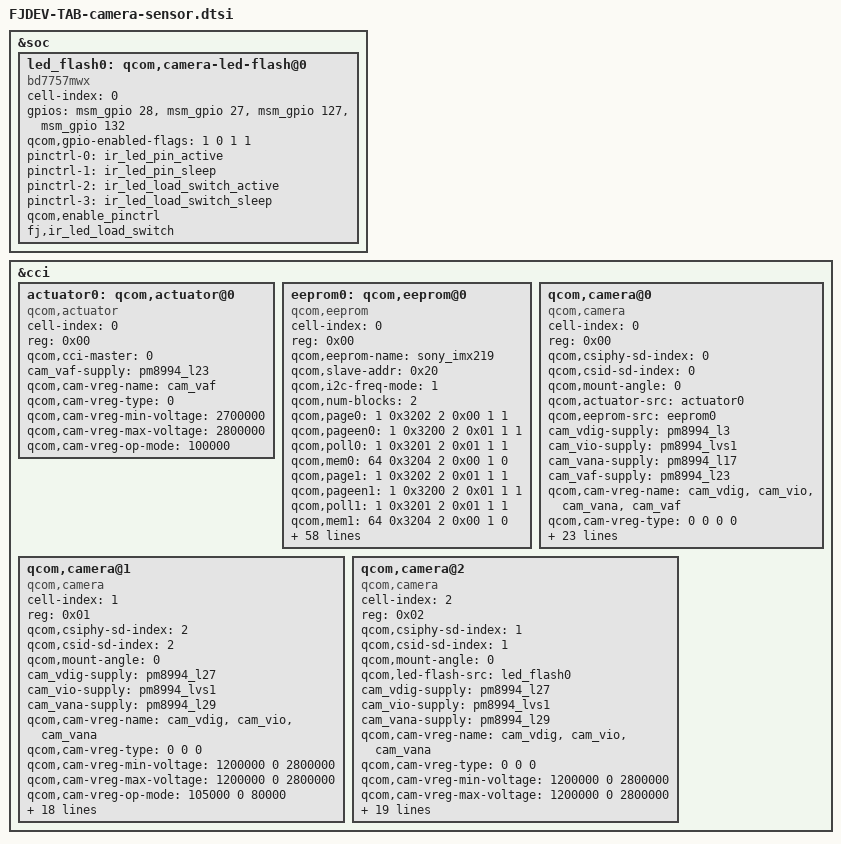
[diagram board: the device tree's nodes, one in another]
/*
 * Copyright (c) 2015, The Linux Foundation. All rights reserved.
 *
 * This program is free software; you can redistribute it and/or modify
 * it under the terms of the GNU General Public License version 2 and
 * only version 2 as published by the Free Software Foundation.
 *
 * This program is distributed in the hope that it will be useful,
 * but WITHOUT ANY WARRANTY; without even the implied warranty of
 * MERCHANTABILITY or FITNESS FOR A PARTICULAR PURPOSE.  See the
 * GNU General Public License for more details.
 */
/*----------------------------------------------------------------------------*/
// COPYRIGHT(C) FUJITSU LIMITED 2015-2016
/*----------------------------------------------------------------------------*/

/* FUJITSU:2016-02-05 FJ_CAMERA_CUSTOM start */
&soc {
    led_flash0: qcom,camera-led-flash@0 {
		cell-index = <0>;
		compatible = "bd7757mwx";
		//		CONTROL_1			CONTROL_2			IRLED_EN		IRLED_XFAULT
		gpios = <&msm_gpio 28 0>, <&msm_gpio 27 0>, <&msm_gpio 127 2>, <&msm_gpio 132 2>;
		qcom,gpio-enabled-flags = <1 0 1 1>;
		pinctrl-names = "led_active", "led_sleep", "load_switch_active", "load_switch_sleep";
		pinctrl-0 = <&ir_led_pin_active>;
		pinctrl-1 = <&ir_led_pin_sleep>;
		pinctrl-2 = <&ir_led_load_switch_active>;
		pinctrl-3 = <&ir_led_load_switch_sleep>;
		qcom,enable_pinctrl;
		fj,ir_led_load_switch;
	};
};

&cci {
	actuator0: qcom,actuator@0 {
		cell-index = <0>;
		reg = <0x00>;
		compatible = "qcom,actuator";
		qcom,cci-master = <0>;
		cam_vaf-supply = <&pm8994_l23>;
		qcom,cam-vreg-name = "cam_vaf";
		qcom,cam-vreg-type = <0>;
		qcom,cam-vreg-min-voltage = <2700000>;
		qcom,cam-vreg-max-voltage = <2800000>;
		qcom,cam-vreg-op-mode = <100000>;
	};
	eeprom0: qcom,eeprom@0 {
		cell-index = <0>;
		reg = <0x00>;
		qcom,eeprom-name = "sony_imx219";
		compatible = "qcom,eeprom";
		qcom,slave-addr = <0x20>;
		qcom,i2c-freq-mode = <1>;
		qcom,num-blocks = <2>;

        qcom,page0 = <1 0x3202 2 0x00 1 1>;
		qcom,pageen0 = <1 0x3200 2 0x01 1 1>;
        qcom,poll0 = <1 0x3201 2 0x01 1 1>;
        qcom,mem0 = <64 0x3204 2 0x00 1 0>;
        qcom,page1 = <1 0x3202 2 0x01 1 1>;
		qcom,pageen1 = <1 0x3200 2 0x01 1 1>;
        qcom,poll1 = <1 0x3201 2 0x01 1 1>;
        qcom,mem1 = <64 0x3204 2 0x00 1 0>;

		fj,setup-data-num  = <12>;
		// i2c slave addr, reg addr, write reg val, delay time [msec]
		fj,setup-data0 = <0x20 0x0100 2 0x00 1 1>; //standby
		fj,setup-data1 = <0x20 0x30EB 2 0x05 1 1>; //access command
		fj,setup-data2 = <0x20 0x30EB 2 0x0C 1 1>; //
		fj,setup-data3 = <0x20 0x300A 2 0xFF 1 1>; //
		fj,setup-data4 = <0x20 0x300B 2 0xFF 1 1>; //
		fj,setup-data5 = <0x20 0x30EB 2 0x05 1 1>; //
		fj,setup-data6 = <0x20 0x30EB 2 0x09 1 1>; //
		fj,setup-data7 = <0x20 0x3302 2 0x01 1 1>; //clock
		fj,setup-data8 = <0x20 0x3303 2 0x2C 1 1>; //clock
		fj,setup-data9 = <0x20 0x012A 2 0x13 1 1>; //frequency
		fj,setup-data10 = <0x20 0x012B 2 0x5B 1 1>; //frequency
		fj,setup-data11 = <0x20 0x3300 2 0x00 1 1>; //ecc

		fj,use-qcom-chksum = <0>;
		fj,custom-read-seq = <1>;

		cam_vdig-supply = <&pm8994_l3>;
		cam_vio-supply = <&pm8994_lvs1>;
		cam_vana-supply = <&pm8994_l17>;
		qcom,cam-vreg-name = "cam_vdig", "cam_vio", "cam_vana";
		qcom,cam-vreg-type = <0 0 0>;
		qcom,cam-vreg-min-voltage = <1200000 0 2800000>;
		qcom,cam-vreg-max-voltage = <1200000 0 2800000>;
		qcom,cam-vreg-op-mode = <105000 0 80000>;
		qcom,gpio-no-mux = <0>;
		pinctrl-names = "cam_default", "cam_suspend";
		pinctrl-0 = <&cam_sensor_mclk0_active &cam_sensor_rear_active>;
		pinctrl-1 = <&cam_sensor_mclk0_suspend &cam_sensor_rear_suspend>;
		gpios = <&msm_gpio 13 0>,
			<&msm_gpio 92 0>;
		qcom,gpio-reset = <1>;
		qcom,gpio-req-tbl-num = <0 1>;
		qcom,gpio-req-tbl-flags = <0 0>;
		qcom,gpio-req-tbl-label = "CAMIF_MCLK0",
					  "CAM_RESET0";
		qcom,cam-power-seq-type =
			"sensor_gpio","sensor_vreg", "sensor_vreg", "sensor_vreg",
			"sensor_clk", "sensor_gpio", "sensor_i2c_mux";
		qcom,cam-power-seq-val =
			"sensor_gpio_reset", "cam_vana", "cam_vio", "cam_vdig",
			"sensor_cam_mclk", "sensor_gpio_reset", "none";
		qcom,cam-power-seq-cfg-val = <0 1 1 1 19350000 1 0>;
		qcom,cam-power-seq-delay = <1 0 0 0 1 1 0>;

		qcom,gpio-set-tbl-num = <1 1>;
		qcom,gpio-set-tbl-flags = <0 2>;
		qcom,gpio-set-tbl-delay = <1000 1000>;

		qcom,cam-power-down-seq-type =
			"sensor_i2c_mux","sensor_clk", "sensor_gpio", "sensor_vreg",
			"sensor_vreg", "sensor_vreg";
		qcom,cam-power-down-seq-val =
			"none", "sensor_cam_mclk", "sensor_gpio_reset", "cam_vio",
			"cam_vdig", "cam_vana";
		qcom,cam-power-down-seq-cfg-val = <0 0 0 0 0 0>;
		qcom,cam-power-down-seq-delay = <0 1 1 0 0 1>;

		qcom,cci-master = <0>;
		clocks = <&clock_mmss clk_mclk0_clk_src>,
				<&clock_mmss clk_camss_mclk0_clk>;
		clock-names = "cam_src_clk", "cam_clk";
	};

	qcom,camera@0 {
		cell-index = <0>;
		compatible = "qcom,camera";
		reg = <0x00>;
		qcom,csiphy-sd-index = <0>;
		qcom,csid-sd-index = <0>;
		qcom,mount-angle = <0>;
		qcom,actuator-src = <&actuator0>;
		qcom,eeprom-src = <&eeprom0>;
//		qcom,led-flash-src = <&led_flash0>;
		cam_vdig-supply = <&pm8994_l3>;
		cam_vio-supply = <&pm8994_lvs1>;
		cam_vana-supply = <&pm8994_l17>;
		cam_vaf-supply = <&pm8994_l23>;
		qcom,cam-vreg-name = "cam_vdig", "cam_vio", "cam_vana", "cam_vaf";
		qcom,cam-vreg-type = <0 0 0 0>;
		qcom,cam-vreg-min-voltage = <1200000 0 2800000 2700000>;
		qcom,cam-vreg-max-voltage = <1200000 0 2800000 2800000>;
		qcom,cam-vreg-op-mode = <105000 0 80000 100000>;
		qcom,gpio-no-mux = <0>;
		pinctrl-names = "cam_default", "cam_suspend";
		pinctrl-0 = <&cam_sensor_mclk0_active &cam_sensor_rear_active>;
		pinctrl-1 = <&cam_sensor_mclk0_suspend &cam_sensor_rear_suspend>;
		gpios = <&msm_gpio 13 0>,
			<&msm_gpio 92 0>;
		qcom,gpio-reset = <1>;
		qcom,gpio-req-tbl-num = <0 1>;
		qcom,gpio-req-tbl-flags = <0 0>;
		qcom,gpio-req-tbl-label = "CAMIF_MCLK0",
					  "CAM_RESET0";
		qcom,csi-lane-assign = <0x4320>;
		qcom,csi-lane-mask = <0x1F>;
		qcom,sensor-position = <0>;
		qcom,sensor-mode = <0>;
		qcom,cci-master = <0>;
		status = "ok";
		clocks = <&clock_mmss clk_mclk0_clk_src>,
				<&clock_mmss clk_camss_mclk0_clk>;
		clock-names = "cam_src_clk", "cam_clk";
	};

	qcom,camera@1 {
		cell-index = <1>;
		compatible = "qcom,camera";
		reg = <0x01>;
		qcom,csiphy-sd-index = <2>;
		qcom,csid-sd-index = <2>;
		qcom,mount-angle = <0>;
		cam_vdig-supply = <&pm8994_l27>;
		cam_vio-supply = <&pm8994_lvs1>;
		cam_vana-supply = <&pm8994_l29>;
		qcom,cam-vreg-name = "cam_vdig", "cam_vio", "cam_vana";
		qcom,cam-vreg-type = <0 0 0>;
		qcom,cam-vreg-min-voltage = <1200000 0 2800000>;
		qcom,cam-vreg-max-voltage = <1200000 0 2800000>;
		qcom,cam-vreg-op-mode = <105000 0 80000>;
		qcom,gpio-no-mux = <0>;
		pinctrl-names = "cam_default", "cam_suspend";
		pinctrl-0 = <&cam_sensor_mclk2_active &cam_sensor_rear_active>;
		pinctrl-1 = <&cam_sensor_mclk2_suspend &cam_sensor_rear_suspend>;
		gpios = <&msm_gpio 15 0>,
			<&msm_gpio 91 0>;
		qcom,gpio-reset = <1>;
		qcom,gpio-req-tbl-num = <0 1>;
		qcom,gpio-req-tbl-flags = <0 0>;
		qcom,gpio-req-tbl-label = "CAMIF_MCLK2",
					  "CAM_RESET1";
		qcom,csi-lane-assign = <0x4320>;
		qcom,csi-lane-mask = <0x7>;
		qcom,sensor-position = <1>;
		qcom,sensor-mode = <0>;
		qcom,cci-master = <1>;
		status = "ok";
		clocks = <&clock_mmss clk_mclk2_clk_src>,
				<&clock_mmss clk_camss_mclk2_clk>;
		clock-names = "cam_src_clk", "cam_clk";
	};

	qcom,camera@2 {
		cell-index = <2>;
		compatible = "qcom,camera";
		reg = <0x02>;
		qcom,csiphy-sd-index = <1>;
		qcom,csid-sd-index = <1>;
		qcom,mount-angle = <0>;
		qcom,led-flash-src = <&led_flash0>;
		cam_vdig-supply = <&pm8994_l27>;
		cam_vio-supply = <&pm8994_lvs1>;
		cam_vana-supply = <&pm8994_l29>;
		qcom,cam-vreg-name = "cam_vdig", "cam_vio", "cam_vana";
		qcom,cam-vreg-type = <0 0 0>;
		qcom,cam-vreg-min-voltage = <1200000 0 2800000>;
		qcom,cam-vreg-max-voltage = <1200000 0 2800000>;
		qcom,cam-vreg-op-mode = <105000 0 80000>;
		qcom,gpio-no-mux = <0>;
		pinctrl-names = "cam_default", "cam_suspend";
		pinctrl-0 = <&cam_sensor_mclk1_active &cam_sensor_ir_active>;
		pinctrl-1 = <&cam_sensor_mclk1_suspend &cam_sensor_ir_suspend>;
		gpios = <&msm_gpio 14 0>,
			<&msm_gpio 110 0>;
		qcom,gpio-reset = <1>;
		qcom,gpio-req-tbl-num = <0 1>;
		qcom,gpio-req-tbl-flags = <0 0>;
		qcom,gpio-req-tbl-label = "CAMIF_MCLK1",
					  "ICAM_RESET";
		qcom,csi-lane-assign = <0x4320>;
		qcom,csi-lane-mask = <0x7>;
		qcom,sensor-position = <1>;
		qcom,sensor-mode = <0>;
		qcom,cci-master = <0>;
		status = "ok";
		clocks = <&clock_mmss clk_mclk1_clk_src>,
				<&clock_mmss clk_camss_mclk1_clk>;
		clock-names = "cam_src_clk", "cam_clk";
	};
};
/* FUJITSU:2016-02-05 FJ_CAMERA_CUSTOM end */
